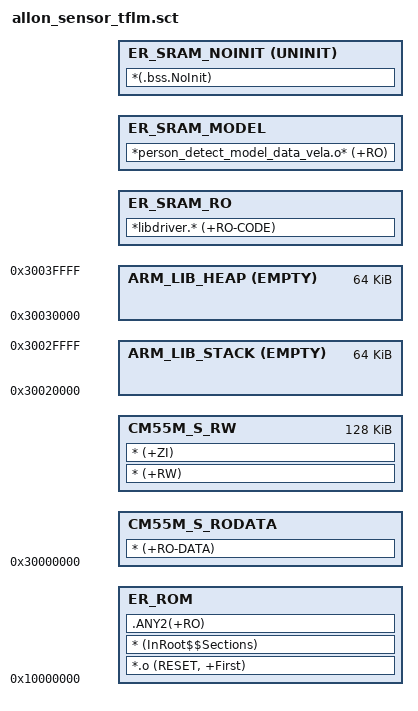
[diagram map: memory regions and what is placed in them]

#include "WE2_device_addr.h"

/*--------------------- Flash Configuration ----------------------------------*/
#define CM55M_ROM_BASE     0x10000000
#define CM55M_ROM_SIZE     0x00040000

/*--------------------- Embedded RAM Configuration ---------------------------*/
#define CM55M_DATA_BASE     0x30000000
#define CM55M_DATA_SIZE     0x00040000

#define CM55M_SRAM_START	0x34000000
#define CM55M_SRAM_BASE     BOOT2NDLOADER_BASE
#define CM55M_SRAM_SIZE     0x00200000-(CM55M_SRAM_BASE-CM55M_SRAM_START)

/*--------------------- Stack / Heap Configuration ---------------------------*/
#define __STACK_SIZE    0x00010000
#define __HEAP_SIZE     0x00010000
#define CM55M_APP_DATASECT_SIZE  (CM55M_DATA_SIZE - __STACK_SIZE - __HEAP_SIZE)
#define CM55M_APP_SRAMSECT_SIZE  (CM55M_SRAM0_SIZE - __STACK_SIZE - __HEAP_SIZE)
#define EXTRA_BASE     CM55M_DATA_BASE
#define EXTRA_SIZE     CM55M_APP_DATASECT_SIZE
#define __STACK_LIMIT   (EXTRA_BASE + EXTRA_SIZE)
#define __STACK_BASE    (EXTRA_BASE + EXTRA_SIZE + __STACK_SIZE)
#define __HEAP_BASE     (EXTRA_BASE + EXTRA_SIZE + __STACK_SIZE)
#define __HEAP_LIMIT    (EXTRA_BASE + EXTRA_SIZE + __STACK_SIZE + __HEAP_SIZE)

LR_ROM1 CM55M_ROM_BASE CM55M_ROM_SIZE  {                       
  ER_ROM +0 {                                       
   *.o (RESET, +First)
   * (InRoot$$Sections)
   .ANY2(+RO)
  }
}

LR_ROM2 CM55M_DATA_BASE  CM55M_DATA_SIZE{
  CM55M_S_RODATA  +0 { 
   * (+RO-DATA)
  }	 
  CM55M_S_RW +0 CM55M_APP_DATASECT_SIZE{    
   * (+RW)
   * (+ZI) //.ANY2(+ZI) 
  }

  ARM_LIB_STACK __STACK_BASE ALIGN 8 EMPTY -__STACK_SIZE {  
  }
  
  ARM_LIB_HEAP  __HEAP_BASE ALIGN 8 EMPTY __HEAP_SIZE  { 
  }
}

LR_ROM3 CM55M_SRAM_BASE CM55M_SRAM_SIZE {
  ER_SRAM_RO +0 ALIGN 4 {
    *libdriver.* (+RO-CODE)
  }

  ER_SRAM_MODEL +0 ALIGN 4 {
	  *person_detect_model_data_vela.o* (+RO)
  }

  ER_SRAM_NOINIT +0 ALIGN 4 UNINIT {  
    *(.bss.NoInit)
  }
}
